# haltium_bbpr register map
Vendor: Nordic Semiconductor; Series: nRFHaltium; File version: 1
Registers are 32-bit, read-write, reset 0x0 unless marked. A register's access mark holds for its fields unless they carry their own. Offsets are from the block's base; [hi:lo] are bit positions; {n}, {i} and the like mark numbered series; 'fields as' and 'values as' point back to an identical list.

## GLOBAL_TDDCONF_S — TDDCONF
Base 0xBF001000
0x400 SYSPWRUPREQ — System power-up request
  [0] ACTIVE — Activate power-up request
    0=NotActive (Power-up request not active); 1=Active (Power-up request active)
0x404 DBGPWRUPREQ — Debug power-up request
  fields as SYSPWRUPREQ
0x408 TRACEPORTSPEED — Trace port trace clock speed
  [1:0] SPEED — Trace clock speed
    0=Speed25MHz; 1=Speed12500KHz (Speed 12.5MHz); 2=Speed6250KHz (Speed 6.25MHz); 3=Speed3125KHz (Speed 3.125MHz)
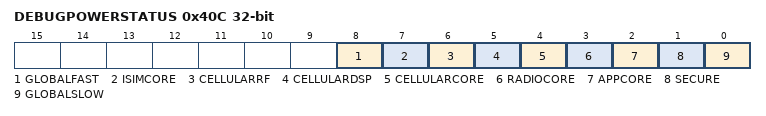
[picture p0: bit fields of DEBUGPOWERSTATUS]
0x40C DEBUGPOWERSTATUS — Debug mode power request status per major power domains
  [all] fields
    0=NotPowerReq (Power not requested); 1=Power requested
  [8] GLOBALFAST — Global fast peripherals domain
  [7] ISIMCORE — ISIM core domain
  [6] CELLULARRF — Cellular RF domain
  [5] CELLULARDSP — Cellular DSP domain
  [4] CELLULARCORE — Cellular core domain
  [3] RADIOCORE — Radio core domain
  [2] APPCORE — Application core domain
  [1] SECURE — Secure domain
  [0] GLOBALSLOW — Global slow peripherals domain

## GLOBAL_GGENERIC60_NS — GENERIC 0
Base 0xBF003000
Same registers: GLOBAL_GGENERIC60_S 0xBF003000 (alternate view of GLOBAL_GGENERIC60_NS), GLOBAL_TSGEN_NS 0xBF041000, GLOBAL_ETB_NS 0xBF044000, GLOBAL_ETR_NS 0xBF045000
0x00 TASKS_GENERICTASK wo — Generic event
  [0] TASKS_GENERICTASK
    1=Trigger task
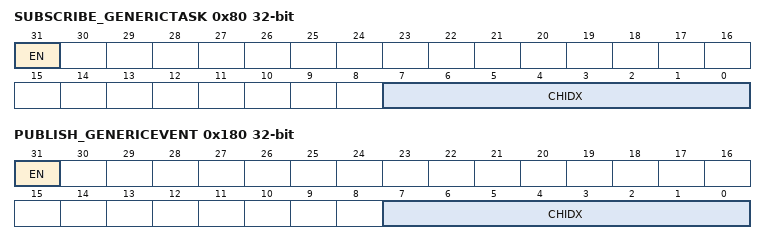
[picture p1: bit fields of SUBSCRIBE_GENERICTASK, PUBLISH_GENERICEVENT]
0x80 SUBSCRIBE_GENERICTASK — Subscribe configuration for task GENERICTASK
  [31] EN
    0=Disabled (Disable subscription); 1=Enabled (Enable subscription)
  [7:0] CHIDX — DPPI channel that task GENERICTASK will subscribe to
0x100 EVENTS_GENERICEVENT — Generic event
  [0] EVENTS_GENERICEVENT
    0=NotGenerated (Event not generated); 1=Generated (Event generated)
0x180 PUBLISH_GENERICEVENT — Publish configuration for event GENERICEVENT
  [31] EN
    0=Disabled (Disable publishing); 1=Enabled (Enable publishing)
  [7:0] CHIDX — DPPI channel that event GENERICEVENT will publish to
0x300 INTEN — Enable or disable interrupt
  [0] GENERICEVENT — Enable or disable interrupt for event GENERICEVENT
    0=Disabled; 1=Enabled
0x304 INTENSET — Enable interrupt
  [0] GENERICEVENT — Write '1' to enable interrupt for event GENERICEVENT
    on read: 0=Disabled (Read: Disabled); 1=Enabled (Read: Enabled) | on write: 1=Set (Enable)
0x308 INTENCLR — Disable interrupt
  [0] GENERICEVENT — Write '1' to disable interrupt for event GENERICEVENT
    on read: 0=Disabled (Read: Disabled); 1=Enabled (Read: Enabled) | on write: 1=Clear (Disable)

## CLIC_NS — Core-Local Interrupt Controller 0
Base 0x43034000
Same registers: CLIC_S 0x53034000
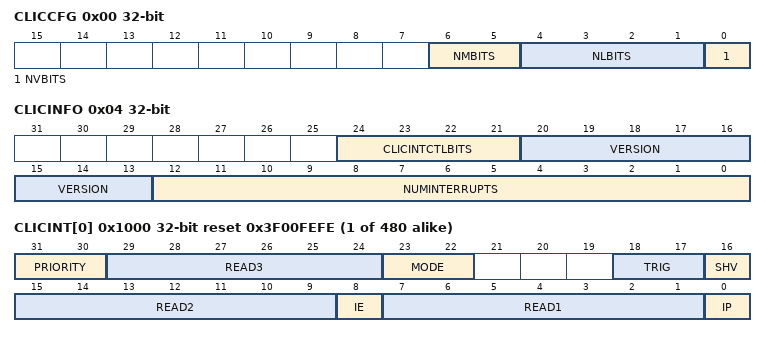
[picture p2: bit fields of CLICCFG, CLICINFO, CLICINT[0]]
0x00 CLICCFG ro — CLIC configuration.
  [6:5] NMBITS — Interrupt previlage mode.
    0=ModeM (All interrupts are M-mode only); 1=ModeS (Interrupts can be S-mode); 2=ModeSU (Interrupts can be S-mode or U-mode)
  [4:1] NLBITS — Interrupt level encoding.
  [0] NVBITS — Selective interrupt hardware vectoring.
    0=NotImplemented (Selective interrupt hardware vectoring is not implemented); 1=Implemented (Selective interrupt hardware vectoring is implemented)
0x04 CLICINFO ro — CLIC information.
  [24:21] CLICINTCTLBITS — Implemented bit in the CLICINT.CTL register.
  [20:13] VERSION
  [12:0] NUMINTERRUPTS — Maximum number of interrupts supported.
{0x1000+4i} CLICINT[{i}] (i=0..479) reset 0x3F00FEFE — Description collection: Interrupt control register for IRQ number [n].
  [31:30] PRIORITY — Interrupt priority.
  [29:24] READ3 ro — Read as 1, write ignored.
  [23:22] MODE ro — Privilege mode.
    0=UserMode; 1=SupervisorMode; 3=MachineMode
  [18:17] TRIG ro — Trigger type and polarity for each interrupt input.
    0=EdgeTriggered (Interrupts are edge-triggered); 1=LevelTriggered (Interrupts are level-triggered); 2=NegativeEdge (Interrupts are positive edge-triggered); 3=PositiveEdge (Interrupts are positive level-triggered)
  [16] SHV ro — Selective Hardware Vectoring.
    0=NonVectored (Interrupt to be non-vectored); 1=Vectored (Hardware vectored)
  [15:9] READ2 ro — Read as 1, write ignored.
  [8] IE — Interrupt enable bit.
    0=Disabled (Interrupt disabled); 1=Enabled (Interrupt enabled)
  [7:1] READ1 ro — Read as 1, write ignored.
  [0] IP — Interrupt Pending bit.
    0=NotPending (Interrupt not pending); 1=Pending (Interrupt pending)
